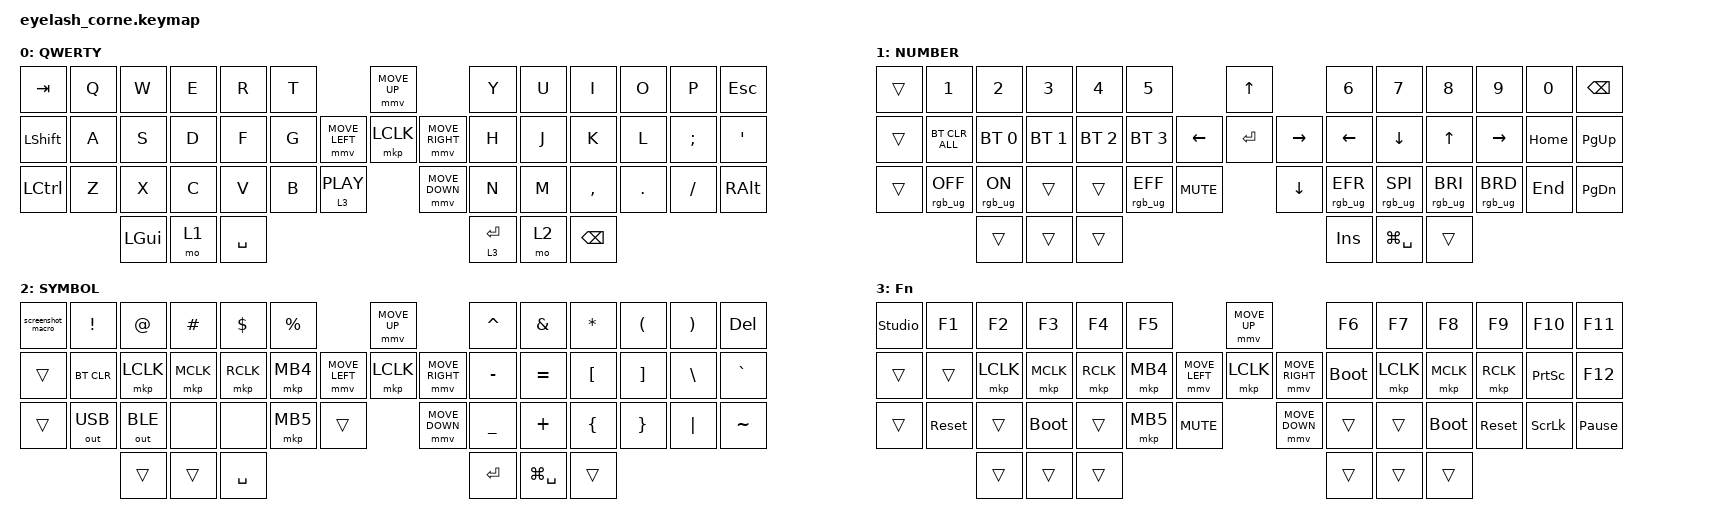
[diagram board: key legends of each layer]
#define ZMK_POINTING_DEFAULT_MOVE_VAL 1200  // 600
#define ZMK_POINTING_DEFAULT_SCRL_VAL 25   // 10

#include <input/processors.dtsi>
#include <zephyr/dt-bindings/input/input-event-codes.h>
#include <behaviors.dtsi>
#include <dt-bindings/zmk/bt.h>
#include <dt-bindings/zmk/keys.h>
#include <dt-bindings/zmk/outputs.h>
#include <dt-bindings/zmk/pointing.h>
#include <dt-bindings/zmk/rgb.h>

&mmv_input_listener { input-processors = <&zip_xy_scaler 2 1>; };

&msc_input_listener { input-processors = <&zip_scroll_scaler 2 1>; };

&msc {
    acceleration-exponent = <0>;      // 0
    time-to-max-speed-ms = <0>;       // 300
    delay-ms = <0>;                   // 0
};

&mmv {
    time-to-max-speed-ms = <0>;
    acceleration-exponent = <0>;
    trigger-period-ms = <10>;
};

/ {
    screenshot_macro: screenshot_macro {
        compatible = "zmk,behavior-macro";
        #binding-cells = <1>;
        bindings = <
            &kp LCMD
            &kp LSFT
            &kp N4
        >;
    };

    rgb_encoder: rgb_encoder {
        compatible = "zmk,behavior-sensor-rotate";
        #sensor-binding-cells = <0>;
        bindings = <&rgb_ug RGB_BRI>, <&rgb_ug RGB_BRD>;
    };

    scroll_encoder: scroll_encoder {
        compatible = "zmk,behavior-sensor-rotate";
        #sensor-binding-cells = <0>;
        bindings = <&msc SCRL_DOWN>, <&msc SCRL_UP>;

        tap-ms = <100>;
    };

    keymap {
        compatible = "zmk,keymap";

        default_layer {
            display-name = "QWERTY";
            bindings = <
&kp TAB           &kp Q  &kp W  &kp E     &kp R  &kp T                               &mmv MOVE_UP                      &kp Y        &kp U  &kp I      &kp O    &kp P     &kp ESC
&kp LEFT_SHIFT    &kp A  &kp S  &kp D     &kp F  &kp G                     &mmv MOVE_LEFT  &mkp LCLK  &mmv MOVE_RIGHT  &kp H        &kp J  &kp K      &kp L    &kp SEMI  &kp SQT
&kp LCTRL         &kp Z  &kp X  &kp C     &kp V  &kp B        &lt 3 C_PLAY           &mmv MOVE_DOWN                    &kp N        &kp M  &kp COMMA  &kp DOT  &kp FSLH  &kp RALT
                         &kp LGUI  &mo 1  &kp SPACE                                                             &lt 3 ENTER  &mo 2  &kp BSPC
            >;
             sensor-bindings = <&inc_dec_kp C_VOLUME_UP C_VOLUME_DOWN>;
        };

        lower_layer {
            display-name = "NUMBER";
            bindings = <
&trans   &kp N1           &kp N2          &kp N3        &kp N4        &kp N5                                         &kp UP                     &kp N6           &kp N7           &kp N8           &kp N9           &kp N0    &kp BSPC
&trans   &bt BT_CLR_ALL   &bt BT_SEL 0    &bt BT_SEL 1  &bt BT_SEL 2  &bt BT_SEL 3                         &kp LEFT  &kp ENTER  &kp RIGHT       &kp LEFT         &kp DOWN         &kp UP           &kp RIGHT        &kp HOME  &kp PG_UP
&trans   &rgb_ug RGB_OFF  &rgb_ug RGB_ON  &trans        &trans        &rgb_ug RGB_EFF  &kp C_MUTE                    &kp DOWN                   &rgb_ug RGB_EFR  &rgb_ug RGB_SPI  &rgb_ug RGB_BRI  &rgb_ug RGB_BRD  &kp END   &kp PG_DN
                                         &trans        &trans        &trans                                                                    &kp INS          &kp LG(SPACE)    &trans
            >;
            sensor-bindings = <&scroll_encoder>;
        };

        raise_layer {
            display-name = "SYMBOL";
            bindings = <
&screenshot_macro   &kp EXCL      &kp AT        &kp HASH   &kp DLLR   &kp PRCNT                            &mmv MOVE_UP                     &kp CARET  &kp AMPS         &kp ASTRK  &kp LPAR  &kp RPAR  &kp DEL
&trans              &bt BT_CLR    &mkp LCLK     &mkp MCLK  &mkp RCLK  &mkp MB4             &mmv MOVE_LEFT  &mkp LCLK       &mmv MOVE_RIGHT  &kp MINUS  &kp EQUAL        &kp LBKT   &kp RBKT  &kp BSLH  &kp GRAVE
&trans              &out OUT_USB  &out OUT_BLE  &none      &none      &mkp MB5   &trans                    &mmv MOVE_DOWN                   &kp UNDER  &kp PLUS         &kp LBRC   &kp RBRC  &kp PIPE  &kp TILDE
                                    &trans     &trans     &kp SPACE                                                             &kp RET    &kp LG(SPACE)  &trans
            >;
            sensor-bindings = <&scroll_encoder>;
        };

        layer_3 {
            display-name = "Fn";
            bindings = <
&studio_unlock  &kp F1      &kp F2     &kp F3       &kp F4     &kp F5                                  &mmv MOVE_UP                     &kp F6       &kp F7     &kp F8       &kp F9      &kp F10          &kp F11
&trans          &trans      &mkp LCLK  &mkp MCLK    &mkp RCLK  &mkp MB4                &mmv MOVE_LEFT  &mkp LCLK       &mmv MOVE_RIGHT  &bootloader  &mkp LCLK  &mkp MCLK    &mkp RCLK   &kp PRINTSCREEN  &kp F12
&trans          &sys_reset  &trans     &bootloader  &trans     &mkp MB5  &kp C_MUTE                    &mmv MOVE_DOWN                   &trans       &trans     &bootloader  &sys_reset  &kp SCROLLLOCK   &kp PAUSE_BREAK
                                       &trans       &trans     &trans                                                                   &trans       &trans     &trans
            >;
            sensor-bindings = <&scroll_encoder>;
        };
    };
};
